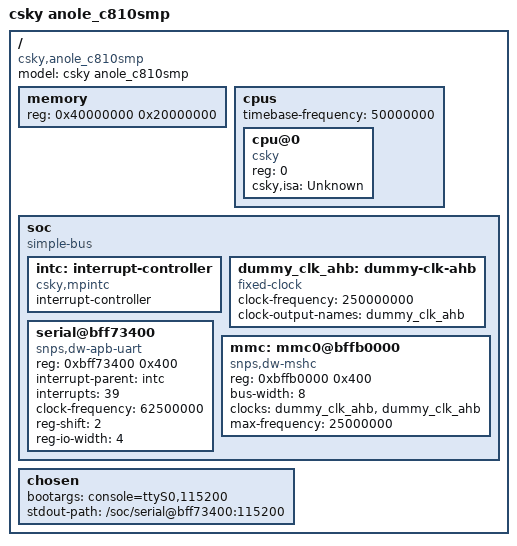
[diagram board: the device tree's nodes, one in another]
/dts-v1/;
/ {
    model = "csky anole_c810smp";
    compatible = "csky,anole_c810smp";
    #address-cells = <1>;
    #size-cells = <1>;

    memory {
        device_type = "memory";
        reg = <0x40000000 0x20000000>;
    };

    cpus {
        #address-cells = <1>;
        #size-cells = <0>;
        timebase-frequency = <50000000>;
        cpu@0 {
            device_type = "cpu";
            reg = <0>;
            status = "okay";
            compatible = "csky";
            csky,isa = "Unknown";
        };
    };

    soc {
        #address-cells = <1>;
        #size-cells = <1>;
        compatible = "simple-bus";
        ranges;

        intc: interrupt-controller {
            compatible = "csky,mpintc";
            interrupt-controller;
            #interrupt-cells = <1>;
        };

        dummy_clk_ahb: dummy-clk-ahb {
            compatible = "fixed-clock";
            clock-frequency = <250000000>;
            clock-output-names = "dummy_clk_ahb";
            #clock-cells = <0>;
        };

        serial@bff73400 {
            compatible = "snps,dw-apb-uart";
            reg = <0xbff73400 0x400>;
            interrupt-parent = <&intc>;
            interrupts = <39>;
            clock-frequency = <62500000>;
            clock-names = "baudclk";
            reg-shift = <2>;
            reg-io-width = <4>;
        };

        mmc: mmc0@bffb0000 {
            compatible = "snps,dw-mshc";
            reg = <0xbffb0000 0x400>;
            bus-width = <8>;
            clocks = <&dummy_clk_ahb>, <&dummy_clk_ahb>;
            clock-names = "biu", "ciu";
            max-frequency = <25000000>;
        };
    };

    chosen {
        bootargs = "console=ttyS0,115200";
        stdout-path = "/soc/serial@bff73400:115200";
    };
};
